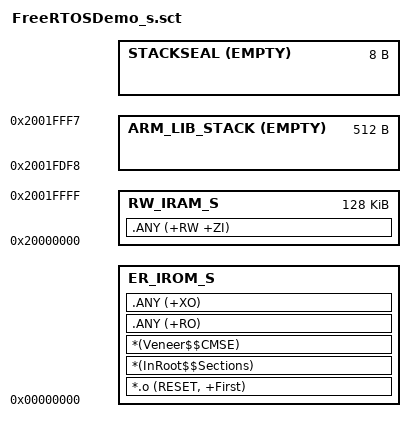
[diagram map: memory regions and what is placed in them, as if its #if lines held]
#! armclang -E --target=arm-arm-none-eabi -mcpu=cortex-m33 -xc -mcmse
; command above MUST be in first line (no comment above!)

;Note: Add '-mcmse' to first line if your software model is "Secure Mode".
;      #! armclang -E --target=arm-arm-none-eabi -mcpu=cortex-m33 -xc -mcmse


/*
;-------- <<< Use Configuration Wizard in Context Menu >>> -------------------
*/

/*--------------------- Flash Configuration ----------------------------------
; <h> Flash Configuration
;   <o0> Flash Base Address <0x0-0xFFFFFFFF:8>
;   <o1> Flash Size (in Bytes) <0x0-0xFFFFFFFF:8>
; </h>
 *----------------------------------------------------------------------------*/
#define __ROM_BASE      0x00000000
#define __ROM_SIZE      0x00200000

/*--------------------- Embedded RAM Configuration ---------------------------
; <h> RAM Configuration
;   <o0> RAM Base Address    <0x0-0xFFFFFFFF:8>
;   <o1> RAM Size (in Bytes) <0x0-0xFFFFFFFF:8>
; </h>
 *----------------------------------------------------------------------------*/
#define __RAM_BASE      0x20000000
#define __RAM_SIZE      0x00020000

/*--------------------- Stack / Heap Configuration ---------------------------
; <h> Stack / Heap Configuration
;   <o0> Stack Size (in Bytes) <0x0-0xFFFFFFFF:8>
;   <o1> Heap Size (in Bytes) <0x0-0xFFFFFFFF:8>
; </h>
 *----------------------------------------------------------------------------*/
#define __STACK_SIZE    0x00000200

/*
;------------- <<< end of configuration section >>> ---------------------------
*/


/*----------------------------------------------------------------------------
  User Stack & Heap boundary definition
 *----------------------------------------------------------------------------*/
#define __STACK_TOP    (__RAM_BASE + __RAM_SIZE - __STACKSEAL_SIZE) /* starts at end of RAM - 8 byte stack seal */

/* ----------------------------------------------------------------------------
  Stack seal size definition
 *----------------------------------------------------------------------------*/
#if defined (__ARM_FEATURE_CMSE) && (__ARM_FEATURE_CMSE == 3U)
#define __STACKSEAL_SIZE   ( 8 )
#else
#define __STACKSEAL_SIZE   ( 0 )
#endif

LR_IROM_S __ROM_BASE __ROM_SIZE ; load region size_region
{
    ER_IROM_S +0 ; load address = execution address
    {
        *.o (RESET, +First)
        *(InRoot$$Sections)
        *(Veneer$$CMSE)         ; This region is marked as Non-Secure callable in partition.h.
        .ANY (+RO)
        .ANY (+XO)
    }

    RW_IRAM_S __RAM_BASE __RAM_SIZE ; RW data
    {
        .ANY (+RW +ZI)
    }

	ARM_LIB_STACK __STACK_TOP EMPTY -__STACK_SIZE ; Reserve empty region for stack
	{
	}

#if defined (__ARM_FEATURE_CMSE) && (__ARM_FEATURE_CMSE == 3U)
	STACKSEAL +0 EMPTY __STACKSEAL_SIZE ; Reserve empty region for stack seal immediately after stack
	{
	}
#endif
}
